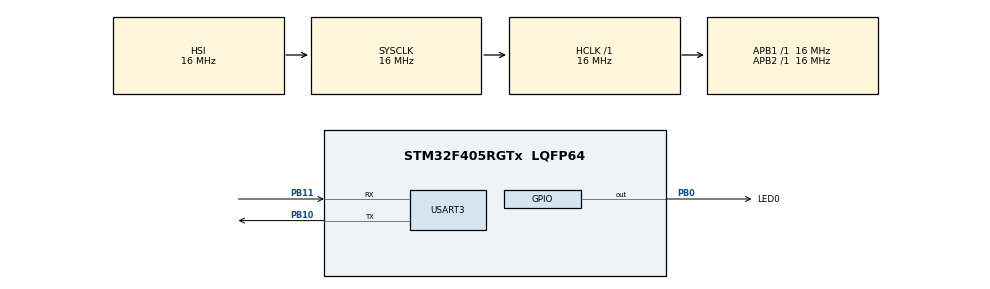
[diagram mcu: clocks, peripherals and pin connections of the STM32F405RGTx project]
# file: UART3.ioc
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FREERTOS.Tasks01=defaultTask,0,128,StartDefaultTask,Default,NULL,Dynamic,NULL,NULL;myTask02,-1,128,StartTask02,Default,NULL,Dynamic,NULL,NULL;myTask03,-1,128,StartTask03,Default,NULL,Dynamic,NULL,NULL
Mcu.Family=STM32F4
Mcu.Name=STM32F405RGTx
Mcu.Package=LQFP64
NVIC.PriorityGroup=NVIC_PRIORITYGROUP_4
NVIC.USART3_IRQn=true\:5\:0\:false\:false\:true\:true\:true\:true\:true
PA13.Mode=Serial_Wire
PA13.Signal=SYS_JTMS-SWDIO
PA14.Mode=Serial_Wire
PA14.Signal=SYS_JTCK-SWCLK
PB0.GPIO_Label=LED0
PB0.Signal=GPIO_Output
PB10.Mode=Asynchronous
PB10.Signal=USART3_TX
PB11.Mode=Asynchronous
PB11.Signal=USART3_RX
ProjectManager.HeapSize=0x200
ProjectManager.StackSize=0x400
ProjectManager.TargetToolchain=STM32CubeIDE
RCC.AHBFreq_Value=16000000
RCC.APB1Freq_Value=16000000
RCC.APB2Freq_Value=16000000
RCC.CortexFreq_Value=16000000
RCC.HSE_VALUE=25000000
RCC.HSI_VALUE=16000000
RCC.LSE_VALUE=32768
RCC.SYSCLKFreq_VALUE=16000000
RCC.VCOOutputFreq_Value=192000000
USART3.VirtualMode=VM_ASYNC
VP_FREERTOS_VS_CMSIS_V1.Mode=CMSIS_V1
board=custom

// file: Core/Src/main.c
/* USER CODE BEGIN Header */
/**
  ******************************************************************************
  * @file           : main.c
  * @brief          : Main program body
  ******************************************************************************
  * @attention
  *
  * Copyright (c) 2022 STMicroelectronics.
  * All rights reserved.
  *
  * This software is licensed under terms that can be found in the LICENSE file
  * in the root directory of this software component.
  * If no LICENSE file comes with this software, it is provided AS-IS.
  *
  ******************************************************************************
  */
/* USER CODE END Header */
#include "main.h"
#include "cmsis_os.h"

/* USER CODE BEGIN Includes */
	uint8_t u8_RxBuff[30];
	uint8_t u8_RxData;
	uint8_t u8_TxBuff[30] = "Program is running.../n/r";
	uint8_t _rxIndex;
	uint8_t TxFlag = 0;
/* USER CODE END Includes */

UART_HandleTypeDef huart3;

osThreadId defaultTaskHandle;
osThreadId myTask02Handle;
osThreadId myTask03Handle;

void SystemClock_Config(void);
static void MX_GPIO_Init(void);
static void MX_USART3_UART_Init(void);
void StartDefaultTask(void const * argument);
void StartTask02(void const * argument);
void StartTask03(void const * argument);

int main(void)
{

  /* MCU Configuration--------------------------------------------------------*/

  /* Reset of all peripherals, Initializes the Flash interface and the Systick. */
  HAL_Init();

  /* Configure the system clock */
  SystemClock_Config();

  /* Initialize all configured peripherals */
  MX_GPIO_Init();
  MX_USART3_UART_Init();

  /* Create the thread(s) */
  /* definition and creation of defaultTask */
  osThreadDef(defaultTask, StartDefaultTask, osPriorityNormal, 0, 128);
  defaultTaskHandle = osThreadCreate(osThread(defaultTask), NULL);

  /* definition and creation of myTask02 */
  osThreadDef(myTask02, StartTask02, osPriorityBelowNormal, 0, 128);
  myTask02Handle = osThreadCreate(osThread(myTask02), NULL);

  /* definition and creation of myTask03 */
  osThreadDef(myTask03, StartTask03, osPriorityBelowNormal, 0, 128);
  myTask03Handle = osThreadCreate(osThread(myTask03), NULL);

  /* Start scheduler */
  osKernelStart();

  /* We should never get here as control is now taken by the scheduler */
  /* Infinite loop */
  while (1)
  {

    /* USER CODE BEGIN 3 */
	  HAL_GPIO_TogglePin(LED0_GPIO_Port, LED0_Pin);
	  HAL_Delay(500);
  }
  /* USER CODE END 3 */
}

void SystemClock_Config(void)
{
  RCC_OscInitTypeDef RCC_OscInitStruct = {0};
  RCC_ClkInitTypeDef RCC_ClkInitStruct = {0};

  /** Configure the main internal regulator output voltage
  */
  __HAL_RCC_PWR_CLK_ENABLE();
  __HAL_PWR_VOLTAGESCALING_CONFIG(PWR_REGULATOR_VOLTAGE_SCALE1);

  /** Initializes the RCC Oscillators according to the specified parameters
  * in the RCC_OscInitTypeDef structure.
  */
  RCC_OscInitStruct.OscillatorType = RCC_OSCILLATORTYPE_HSI;
  RCC_OscInitStruct.HSIState = RCC_HSI_ON;
  RCC_OscInitStruct.HSICalibrationValue = RCC_HSICALIBRATION_DEFAULT;
  RCC_OscInitStruct.PLL.PLLState = RCC_PLL_NONE;
  if (HAL_RCC_OscConfig(&RCC_OscInitStruct) != HAL_OK)
  {
    Error_Handler();
  }

  /** Initializes the CPU, AHB and APB buses clocks
  */
  RCC_ClkInitStruct.ClockType = RCC_CLOCKTYPE_HCLK|RCC_CLOCKTYPE_SYSCLK
                              |RCC_CLOCKTYPE_PCLK1|RCC_CLOCKTYPE_PCLK2;
  RCC_ClkInitStruct.SYSCLKSource = RCC_SYSCLKSOURCE_HSI;
  RCC_ClkInitStruct.AHBCLKDivider = RCC_SYSCLK_DIV1;
  RCC_ClkInitStruct.APB1CLKDivider = RCC_HCLK_DIV1;
  RCC_ClkInitStruct.APB2CLKDivider = RCC_HCLK_DIV1;

  if (HAL_RCC_ClockConfig(&RCC_ClkInitStruct, FLASH_LATENCY_0) != HAL_OK)
  {
    Error_Handler();
  }
}

static void MX_USART3_UART_Init(void)
{

  huart3.Instance = USART3;
  huart3.Init.BaudRate = 115200;
  huart3.Init.WordLength = UART_WORDLENGTH_8B;
  huart3.Init.StopBits = UART_STOPBITS_1;
  huart3.Init.Parity = UART_PARITY_NONE;
  huart3.Init.Mode = UART_MODE_TX_RX;
  huart3.Init.HwFlowCtl = UART_HWCONTROL_NONE;
  huart3.Init.OverSampling = UART_OVERSAMPLING_16;
  if (HAL_UART_Init(&huart3) != HAL_OK)
  {
    Error_Handler();
  }

}

static void MX_GPIO_Init(void)
{
  GPIO_InitTypeDef GPIO_InitStruct = {0};

  /* GPIO Ports Clock Enable */
  __HAL_RCC_GPIOB_CLK_ENABLE();
  __HAL_RCC_GPIOA_CLK_ENABLE();

  /*Configure GPIO pin Output Level */
  HAL_GPIO_WritePin(LED0_GPIO_Port, LED0_Pin, GPIO_PIN_RESET);

  /*Configure GPIO pin : LED0_Pin */
  GPIO_InitStruct.Pin = LED0_Pin;
  GPIO_InitStruct.Mode = GPIO_MODE_OUTPUT_PP;
  GPIO_InitStruct.Pull = GPIO_NOPULL;
  GPIO_InitStruct.Speed = GPIO_SPEED_FREQ_LOW;
  HAL_GPIO_Init(LED0_GPIO_Port, &GPIO_InitStruct);

}

void StartDefaultTask(void const * argument)
{
  for(;;)
  {
    osDelay(1);
  }
}

void StartTask02(void const * argument)
{
  for(;;)
  {
    osDelay(1);
  }
}

void StartTask03(void const * argument)
{
  for(;;)
  {
    osDelay(1);
  }
}

void Error_Handler(void)
{
  __disable_irq();
  while (1)
  {
  }
}
